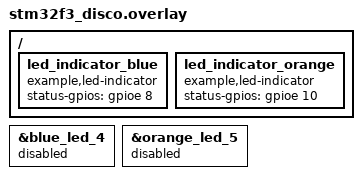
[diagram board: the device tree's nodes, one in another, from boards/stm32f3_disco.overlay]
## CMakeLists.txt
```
cmake_minimum_required(VERSION 3.22.0)

set(ZEPHYR_EXTRA_MODULES "${CMAKE_SOURCE_DIR}/modules/led_indicator")

find_package(Zephyr REQUIRED HINTS $ENV{ZEPHYR_BASE})
project(pm_shell)

target_sources(app PRIVATE src/main.c)
```

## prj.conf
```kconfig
CONFIG_SHELL=y
CONFIG_SHELL_BACKEND_SERIAL=y
CONFIG_DEVICE_SHELL=y
CONFIG_PM=y
CONFIG_PM_DEVICE=y
CONFIG_PM_DEVICE_SHELL=y
CONFIG_LED_INDICATOR=y
```

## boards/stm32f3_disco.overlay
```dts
/ {
    led_indicator_blue: led_indicator_blue {
        compatible = "example,led-indicator";
        status-gpios = <&gpioe 8 GPIO_ACTIVE_HIGH>;  /* blue_led_4 */
        status = "okay";
    };

    led_indicator_orange: led_indicator_orange {
        compatible = "example,led-indicator";
        status-gpios = <&gpioe 10 GPIO_ACTIVE_HIGH>;  /* orange_led_5 */
        status = "okay";
    };
};

/* Hand these pins exclusively to the led_indicator driver. */
&blue_led_4 {
    status = "disabled";
};

&orange_led_5 {
    status = "disabled";
};
```

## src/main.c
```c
#include <zephyr/kernel.h>
#include <zephyr/device.h>

#define LED_INDICATOR_BLUE   DEVICE_DT_GET(DT_NODELABEL(led_indicator_blue))
#define LED_INDICATOR_ORANGE DEVICE_DT_GET(DT_NODELABEL(led_indicator_orange))

int main(void)
{
	if (!device_is_ready(LED_INDICATOR_BLUE) || !device_is_ready(LED_INDICATOR_ORANGE)) {
		printk("LED indicator device not ready\n");
		return 0;
	}

	printk("PM shell example ready — both LEDs are ON.\n");
	printk("Use 'device list' to see device names.\n");
	printk("Use 'pm device suspend led_indicator_blue' to turn blue LED off.\n");
	printk("Use 'pm device suspend led_indicator_orange' to turn orange LED off.\n");
	printk("Use 'pm device resume <name>' to turn a LED back on.\n");

	return 0;
}
```
